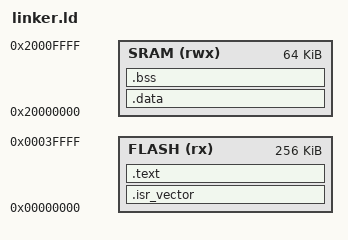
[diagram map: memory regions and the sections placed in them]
ENTRY(Reset_Handler)

MEMORY
{
    FLASH (rx)  : ORIGIN = 0x00000000, LENGTH = 256K
    SRAM  (rwx) : ORIGIN = 0x20000000, LENGTH = 64K
}

SECTIONS
{
    .isr_vector :
    {
        KEEP(*(.isr_vector))
    } > FLASH

    .text :
    {
        *(.text*)
        *(.rodata*)
        . = ALIGN(4);
    } > FLASH

    .data : AT (ADDR(.text) + SIZEOF(.text))
    {
        _sdata = .;
        *(.data*)
        . = ALIGN(4);
        _edata = .;
    } > SRAM

    .bss (NOLOAD) :
    {
        _sbss = .;
        *(.bss*)
        *(COMMON)
        . = ALIGN(4);
        _ebss = .;
    } > SRAM

    _sidata = LOADADDR(.data);
    _estack = ORIGIN(SRAM) + LENGTH(SRAM);
}
